# RockChip_RK3588 register map
Vendor: RockChip Electronics Co., Ltd.; Series: RK3588; File version: 0.1
Registers are 32-bit, read-write, no defined reset value unless marked. A register's access mark holds for its fields unless they carry their own. Offsets are from the block's base; [hi:lo] are bit positions; {n}, {i} and the like mark numbered series; 'fields as' and 'values as' point back to an identical list.

## CRU_SECURE
Base 0xFD7D0000
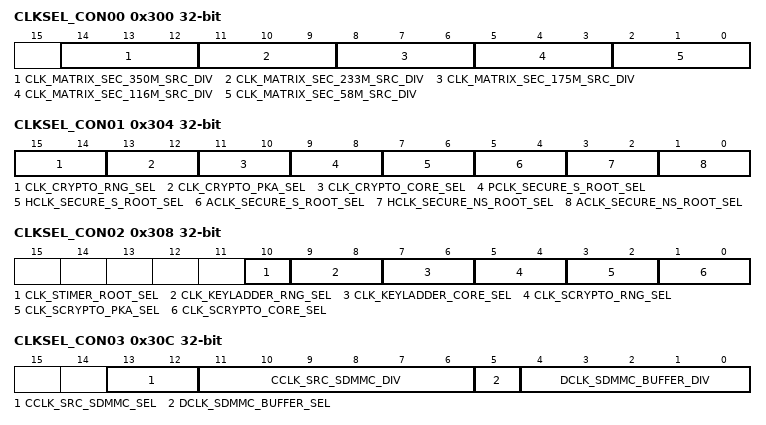
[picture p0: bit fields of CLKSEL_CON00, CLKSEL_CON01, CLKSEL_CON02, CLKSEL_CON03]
0x300 CLKSEL_CON00 — Internal clock select and division register 0
  [14:12] CLK_MATRIX_SEC_350M_SRC_DIV — Divide clk_matrix_sec_350m_src by (div_con + 1).
  [11:9] CLK_MATRIX_SEC_233M_SRC_DIV — Divide clk_matrix_sec_233m_src by (div_con + 1).
  [8:6] CLK_MATRIX_SEC_175M_SRC_DIV — Divide clk_matrix_sec_175m_src by (div_con + 1).
  [5:3] CLK_MATRIX_SEC_116M_SRC_DIV — Divide clk_matrix_sec_116m_src by (div_con + 1).
  [2:0] CLK_MATRIX_SEC_58M_SRC_DIV — Divide clk_matrix_sec_58m_src by (div_con + 1).
0x304 CLKSEL_CON01 — Internal clock select and division register 1
  [15:14] CLK_CRYPTO_RNG_SEL — clk_crypto_rng clock mux.
    0=CLK_MATRIX_SEC_175M_SRC; 1=CLK_MATRIX_SEC_116M_SRC; 2=CLK_MATRIX_SEC_58M_SRC; 3=XIN_OSC0_FUNC
  [13:12] CLK_CRYPTO_PKA_SEL — clk_crypto_pka clock mux.
    0=CLK_MATRIX_SEC_350M_SRC; 1=CLK_MATRIX_SEC_233M_SRC; 2=CLK_MATRIX_SEC_116M_SRC; 3=XIN_OSC0_FUNC
  [11:10] CLK_CRYPTO_CORE_SEL — clk_crypto_core clock mux.
    values as CLK_CRYPTO_PKA_SEL
  [9:8] PCLK_SECURE_S_ROOT_SEL — pclk_secure_s_root clock mux.
    0=CLK_MATRIX_SEC_116M_SRC; 1=CLK_MATRIX_SEC_58M_SRC; 2=XIN_OSC0_FUNC
  [7:6] HCLK_SECURE_S_ROOT_SEL — hclk_secure_s_root clock mux.
    values as CLK_CRYPTO_RNG_SEL
  [5:4] ACLK_SECURE_S_ROOT_SEL — aclk_secure_s_root clock mux.
    values as CLK_CRYPTO_PKA_SEL
  [3:2] HCLK_SECURE_NS_ROOT_SEL — hclk_secure_ns_root clock mux.
    0=CLK_MATRIX_150M_SRC; 1=CLK_MATRIX_100M_SRC; 2=CLK_MATRIX_50M_SRC; 3=XIN_OSC0_FUNC
  [1:0] ACLK_SECURE_NS_ROOT_SEL — aclk_secure_ns_root clock mux.
    0=CLK_MATRIX_350M_SRC; 1=CLK_MATRIX_200M_SRC; 2=CLK_MATRIX_100M_SRC; 3=XIN_OSC0_FUNC
0x308 CLKSEL_CON02 — Internal clock select and division register 2
  [10] CLK_STIMER_ROOT_SEL — clk_stimer_root clock mux.
    0=XIN_OSC0_FUNC; 1=CLK_MATRIX_SEC_116M_SRC
  [9:8] CLK_KEYLADDER_RNG_SEL — clk_keyladder_rng clock mux.
    values as CLKSEL_CON01.CLK_CRYPTO_RNG_SEL
  [7:6] CLK_KEYLADDER_CORE_SEL — clk_keyladder_core clock mux.
    values as CLKSEL_CON01.CLK_CRYPTO_PKA_SEL
  [5:4] CLK_SCRYPTO_RNG_SEL — clk_scrypto_rng clock mux.
    values as CLKSEL_CON01.CLK_CRYPTO_RNG_SEL
  [3:2] CLK_SCRYPTO_PKA_SEL — clk_scrypto_pka clock mux.
    values as CLKSEL_CON01.CLK_CRYPTO_PKA_SEL
  [1:0] CLK_SCRYPTO_CORE_SEL — clk_scrypto_core clock mux.
    values as CLKSEL_CON01.CLK_CRYPTO_PKA_SEL
0x30C CLKSEL_CON03 — Internal clock select and division register 3
  [13:12] CCLK_SRC_SDMMC_SEL — cclk_src_sdmmc clock mux.
    0=CLK_GPLL_MUX; 1=CLK_SPLL_MUX; 2=XIN_OSC0_FUNC
  [11:6] CCLK_SRC_SDMMC_DIV — DT50 division register. Divide cclk_src_sdmmc by (div_con + 1).
  [5] DCLK_SDMMC_BUFFER_SEL — dclk_sdmmc_buffer clock mux.
    0=CLK_GPLL_MUX; 1=CLK_SPLL_MUX
  [4:0] DCLK_SDMMC_BUFFER_DIV — Divide dclk_sdmmc_buffer by (div_con + 1).
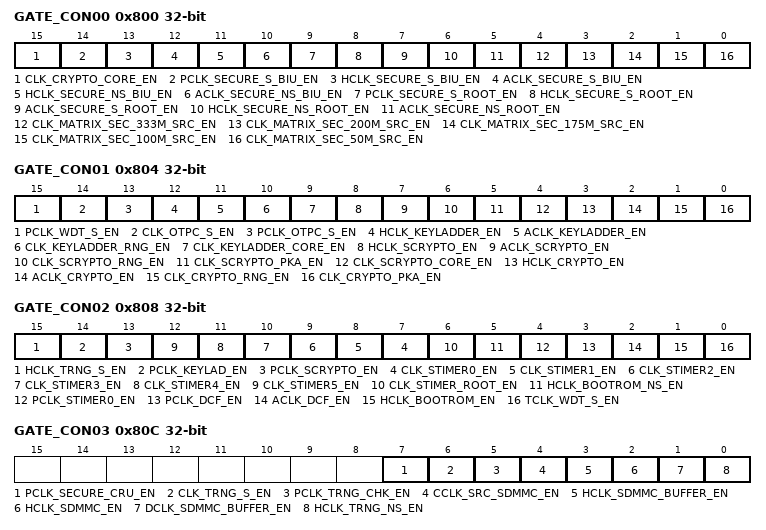
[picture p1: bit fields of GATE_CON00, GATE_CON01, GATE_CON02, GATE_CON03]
0x800 GATE_CON00 — Internal clock gate and division register 0
  [all] fields
    0=ENABLE; 1=DISABLE
  [15] CLK_CRYPTO_CORE_EN — clk_crypto_core clock gating control.
  [14] PCLK_SECURE_S_BIU_EN — pclk_secure_s_biu clock gating control.
  [13] HCLK_SECURE_S_BIU_EN — hclk_secure_s_biu clock gating control.
  [12] ACLK_SECURE_S_BIU_EN — aclk_secure_s_biu clock gating control.
  [11] HCLK_SECURE_NS_BIU_EN — hclk_secure_ns_biu clock gating control.
  [10] ACLK_SECURE_NS_BIU_EN — aclk_secure_ns_biu clock gating control.
  [9] PCLK_SECURE_S_ROOT_EN — pclk_secure_s_root clock gating control.
  [8] HCLK_SECURE_S_ROOT_EN — hclk_secure_s_root clock gating control.
  [7] ACLK_SECURE_S_ROOT_EN — aclk_secure_s_root clock gating control.
  [6] HCLK_SECURE_NS_ROOT_EN — hclk_secure_ns_root clock gating control.
  [5] ACLK_SECURE_NS_ROOT_EN — aclk_secure_ns_root clock gating control.
  [4] CLK_MATRIX_SEC_333M_SRC_EN — clk_matrix_sec_350m_src clock gating control.
  [3] CLK_MATRIX_SEC_200M_SRC_EN — clk_matrix_sec_233m_src clock gating control.
  [2] CLK_MATRIX_SEC_175M_SRC_EN — clk_matrix_sec_175m_src clock gating control.
  [1] CLK_MATRIX_SEC_100M_SRC_EN — clk_matrix_sec_116m_src clock gating control.
  [0] CLK_MATRIX_SEC_50M_SRC_EN — clk_matrix_sec_58m_src clock gating control.
0x804 GATE_CON01 — Internal clock gate and division register 1
  [all] fields
    0=ENABLE; 1=DISABLE
  [15] PCLK_WDT_S_EN — pclk_wdt_s clock gating control.
  [14] CLK_OTPC_S_EN — clk_otpc_s clock gating control.
  [13] PCLK_OTPC_S_EN — pclk_otpc_s clock gating control.
  [12] HCLK_KEYLADDER_EN — hclk_keyladder clock gating control.
  [11] ACLK_KEYLADDER_EN — aclk_keyladder clock gating control.
  [10] CLK_KEYLADDER_RNG_EN — clk_keyladder_rng clock gating control.
  [9] CLK_KEYLADDER_CORE_EN — clk_keyladder_core clock gating control.
  [8] HCLK_SCRYPTO_EN — hclk_scrypto clock gating control.
  [7] ACLK_SCRYPTO_EN — aclk_scrypto clock gating control.
  [6] CLK_SCRYPTO_RNG_EN — clk_scrypto_rng clock gating control.
  [5] CLK_SCRYPTO_PKA_EN — clk_scrypto_pka clock gating control.
  [4] CLK_SCRYPTO_CORE_EN — clk_scrypto_core clock gating control.
  [3] HCLK_CRYPTO_EN — hclk_crypto clock gating control.
  [2] ACLK_CRYPTO_EN — aclk_crypto clock gating control.
  [1] CLK_CRYPTO_RNG_EN — clk_crypto_rng clock gating control.
  [0] CLK_CRYPTO_PKA_EN — clk_crypto_pka clock gating control.
0x808 GATE_CON02 — Internal clock gate and division register 2
  [all] fields
    0=ENABLE; 1=DISABLE
  [15] HCLK_TRNG_S_EN — hclk_trng_s clock gating control.
  [14] PCLK_KEYLAD_EN — pclk_keylad clock gating control.
  [13] PCLK_SCRYPTO_EN — pclk_scrypto clock gating control.
  [n+7] CLK_STIMER{n}_EN (n=0..5) — clk_stimer{n} clock gating control.
  [6] CLK_STIMER_ROOT_EN — clk_stimer_root clock gating control.
  [5] HCLK_BOOTROM_NS_EN — hclk_bootrom_ns clock gating control.
  [4] PCLK_STIMER0_EN — pclk_stimer0 clock gating control.
  [3] PCLK_DCF_EN — pclk_dcf clock gating control.
  [2] ACLK_DCF_EN — aclk_dcf clock gating control.
  [1] HCLK_BOOTROM_EN — hclk_bootrom clock gating control.
  [0] TCLK_WDT_S_EN — tclk_wdt_s clock gating control.
0x80C GATE_CON03 — Internal clock gate and division register 3
  [all] fields
    0=ENABLE; 1=DISABLE
  [7] PCLK_SECURE_CRU_EN — pclk_secure_cru clock gating control.
  [6] CLK_TRNG_S_EN — clk_trng_s clock gating control.
  [5] PCLK_TRNG_CHK_EN — pclk_trng_chk clock gating control.
  [4] CCLK_SRC_SDMMC_EN — cclk_src_sdmmc clock gating control.
  [3] HCLK_SDMMC_BUFFER_EN — hclk_sdmmc_buffer clock gating control.
  [2] HCLK_SDMMC_EN — hclk_sdmmc clock gating control.
  [1] DCLK_SDMMC_BUFFER_EN — dclk_sdmmc_buffer clock gating control.
  [0] HCLK_TRNG_NS_EN — hclk_trng_ns clock gating control.
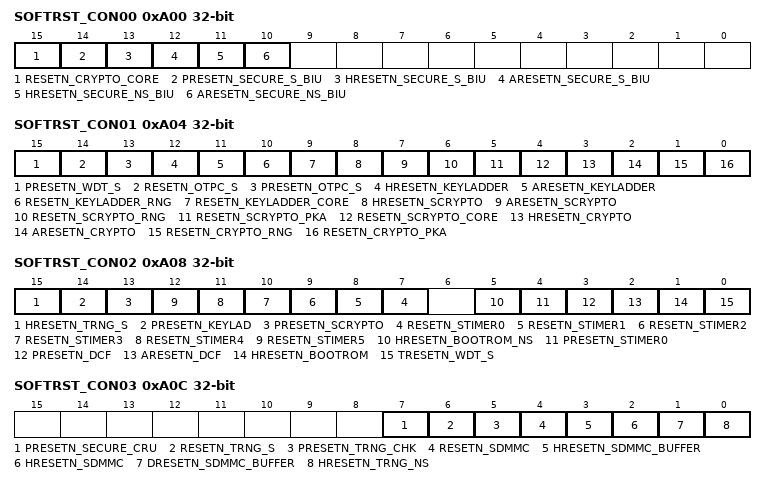
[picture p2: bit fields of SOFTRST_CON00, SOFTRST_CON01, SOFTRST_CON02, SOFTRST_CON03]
0xA00 SOFTRST_CON00 — Internal clock reset register 0
  [15] RESETN_CRYPTO_CORE — When high, reset relative logic
  [14] PRESETN_SECURE_S_BIU — When high, reset relative logic
  [13] HRESETN_SECURE_S_BIU — When high, reset relative logic
  [12] ARESETN_SECURE_S_BIU — When high, reset relative logic
  [11] HRESETN_SECURE_NS_BIU — When high, reset relative logic
  [10] ARESETN_SECURE_NS_BIU — When high, reset relative logic
0xA04 SOFTRST_CON01 — Internal clock reset register 1
  [15] PRESETN_WDT_S — When high, reset relative logic
  [14] RESETN_OTPC_S — When high, reset relative logic
  [13] PRESETN_OTPC_S — When high, reset relative logic
  [12] HRESETN_KEYLADDER — When high, reset relative logic
  [11] ARESETN_KEYLADDER — When high, reset relative logic
  [10] RESETN_KEYLADDER_RNG — When high, reset relative logic
  [9] RESETN_KEYLADDER_CORE — When high, reset relative logic
  [8] HRESETN_SCRYPTO — When high, reset relative logic
  [7] ARESETN_SCRYPTO — When high, reset relative logic
  [6] RESETN_SCRYPTO_RNG — When high, reset relative logic
  [5] RESETN_SCRYPTO_PKA — When high, reset relative logic
  [4] RESETN_SCRYPTO_CORE — When high, reset relative logic
  [3] HRESETN_CRYPTO — When high, reset relative logic
  [2] ARESETN_CRYPTO — When high, reset relative logic
  [1] RESETN_CRYPTO_RNG — When high, reset relative logic
  [0] RESETN_CRYPTO_PKA — When high, reset relative logic
0xA08 SOFTRST_CON02 — Internal clock reset register 2
  [15] HRESETN_TRNG_S — When high, reset relative logic
  [14] PRESETN_KEYLAD — When high, reset relative logic
  [13] PRESETN_SCRYPTO — When high, reset relative logic
  [n+7] RESETN_STIMER{n} (n=0..5) — When high, reset relative logic
  [5] HRESETN_BOOTROM_NS — When high, reset relative logic
  [4] PRESETN_STIMER0 — When high, reset relative logic
  [3] PRESETN_DCF — When high, reset relative logic
  [2] ARESETN_DCF — When high, reset relative logic
  [1] HRESETN_BOOTROM — When high, reset relative logic
  [0] TRESETN_WDT_S — When high, reset relative logic
0xA0C SOFTRST_CON03 — Internal clock reset register 3
  [7] PRESETN_SECURE_CRU — When high, reset relative logic
  [6] RESETN_TRNG_S — When high, reset relative logic
  [5] PRESETN_TRNG_CHK — When high, reset relative logic
  [4] RESETN_SDMMC — When high, reset relative logic
  [3] HRESETN_SDMMC_BUFFER — When high, reset relative logic
  [2] HRESETN_SDMMC — When high, reset relative logic
  [1] DRESETN_SDMMC_BUFFER — When high, reset relative logic
  [0] HRESETN_TRNG_NS — When high, reset relative logic
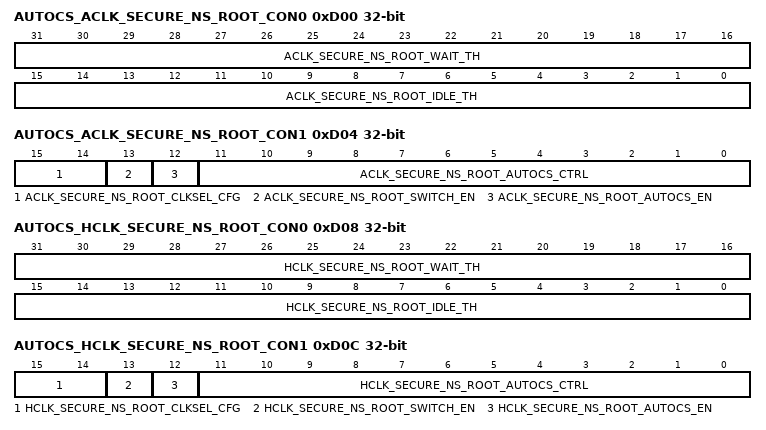
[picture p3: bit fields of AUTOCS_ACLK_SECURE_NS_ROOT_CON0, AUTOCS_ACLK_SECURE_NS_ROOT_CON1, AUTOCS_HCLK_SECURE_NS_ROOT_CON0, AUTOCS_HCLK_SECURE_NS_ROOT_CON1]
0xD00 AUTOCS_ACLK_SECURE_NS_ROOT_CON0 — Auto clock switch control register 0
  [31:16] ACLK_SECURE_NS_ROOT_WAIT_TH — wait_th. Wait time threshold, measured by original clk.
  [15:0] ACLK_SECURE_NS_ROOT_IDLE_TH — idle_th. Idle time threshold, measured by original clk.
0xD04 AUTOCS_ACLK_SECURE_NS_ROOT_CON1 — Auto clock switch control register 1
  [15:14] ACLK_SECURE_NS_ROOT_CLKSEL_CFG — clksel_cfg. Auto switch clock selection.
    0=ORIGINAL_CLK; 1=XIN_OSC0_FUNC_DIV; 2=CLK_RTC_32K
  [13] ACLK_SECURE_NS_ROOT_SWITCH_EN — switch_en.
    1=ENABLE (Enable aclk_secure_ns_root switched to lower frequency when module is inactive.); 0=DISABLE (Disable auto switch function.)
  [12] ACLK_SECURE_NS_ROOT_AUTOCS_EN — autocs_en
    1=ENABLE (Enable aclk_secure_ns_root switch to lower frequency.); 0=DISABLE
  [11:0] ACLK_SECURE_NS_ROOT_AUTOCS_CTRL — autocs_ctrl. Others: Reserved.
    0xFFF=ENABLE (Enable aclk_secure_ns_root switch to lower frequency.); 0=DISABLE
0xD08 AUTOCS_HCLK_SECURE_NS_ROOT_CON0 — Auto clock switch control register 0
  [31:16] HCLK_SECURE_NS_ROOT_WAIT_TH — wait_th. Wait time threshold, measured by original clk.
  [15:0] HCLK_SECURE_NS_ROOT_IDLE_TH — idle_th. Idle time threshold, measured by original clk.
0xD0C AUTOCS_HCLK_SECURE_NS_ROOT_CON1 — Auto clock switch control register 1
  [15:14] HCLK_SECURE_NS_ROOT_CLKSEL_CFG — clksel_cfg. Auto switch clock selection.
    0=ORIGINAL_CLK; 1=XIN_OSC0_FUNC_DIV; 2=CLK_RTC_32K
  [13] HCLK_SECURE_NS_ROOT_SWITCH_EN — switch_en.
    1=ENABLE (Enable hclk_secure_ns_root switched to lower frequency when module is inactive.); 0=DISABLE (Disable auto switch function.)
  [12] HCLK_SECURE_NS_ROOT_AUTOCS_EN — autocs_en
    1=ENABLE (Enable hclk_secure_ns_root switch to lower frequency.); 0=DISABLE
  [11:0] HCLK_SECURE_NS_ROOT_AUTOCS_CTRL — autocs_ctrl. Others: Reserved.
    0xFFF=ENABLE (Enable hclk_secure_ns_root switch to lower frequency.); 0=DISABLE
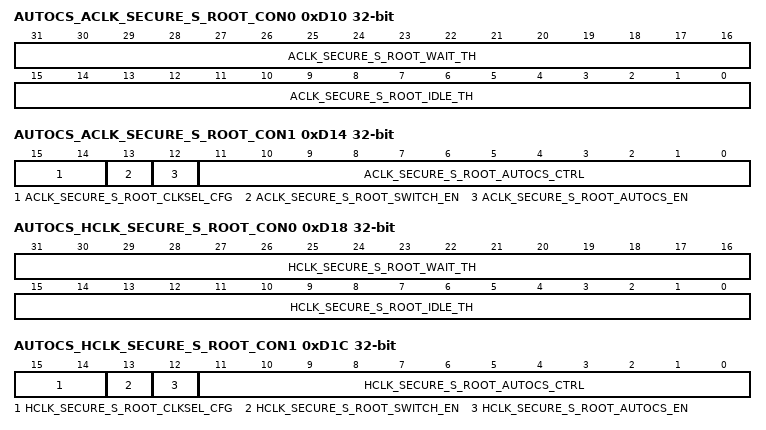
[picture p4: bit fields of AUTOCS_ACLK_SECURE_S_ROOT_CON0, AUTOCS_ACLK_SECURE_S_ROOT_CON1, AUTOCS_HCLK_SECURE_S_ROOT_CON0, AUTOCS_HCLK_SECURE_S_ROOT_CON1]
0xD10 AUTOCS_ACLK_SECURE_S_ROOT_CON0 — Auto clock switch control register 0
  [31:16] ACLK_SECURE_S_ROOT_WAIT_TH — wait_th. Wait time threshold, measured by original clk.
  [15:0] ACLK_SECURE_S_ROOT_IDLE_TH — idle_th. Idle time threshold, measured by original clk.
0xD14 AUTOCS_ACLK_SECURE_S_ROOT_CON1 — Auto clock switch control register 1
  [15:14] ACLK_SECURE_S_ROOT_CLKSEL_CFG — clksel_cfg. Auto switch clock selection.
    0=ORIGINAL_CLK; 1=XIN_OSC0_FUNC_DIV; 2=CLK_RTC_32K
  [13] ACLK_SECURE_S_ROOT_SWITCH_EN — switch_en
    1=ENABLE (Enable aclk_secure_s_root switched to lower frequency when module is inactive.); 0=DISABLE (Disable auto switch function.)
  [12] ACLK_SECURE_S_ROOT_AUTOCS_EN — autocs_en
    1=ENABLE (Enable aclk_secure_s_root switch to lower frequency.); 0=DISABLE
  [11:0] ACLK_SECURE_S_ROOT_AUTOCS_CTRL — autocs_ctrl. Others: Reserved.
    0xFFF=ENABLE (Enable aclk_secure_s_root switch to lower frequency.); 0=DISABLE
0xD18 AUTOCS_HCLK_SECURE_S_ROOT_CON0 — Auto clock switch control register 0
  [31:16] HCLK_SECURE_S_ROOT_WAIT_TH — wait_th. Wait time threshold, measured by original clk.
  [15:0] HCLK_SECURE_S_ROOT_IDLE_TH — idle_th. Idle time threshold, measured by original clk.
0xD1C AUTOCS_HCLK_SECURE_S_ROOT_CON1 — Auto clock switch control register 1
  [15:14] HCLK_SECURE_S_ROOT_CLKSEL_CFG — clksel_cfg. Auto switch clock selection.
    0=ORIGINAL_CLK; 1=XIN_OSC0_FUNC_DIV; 2=CLK_RTC_32K
  [13] HCLK_SECURE_S_ROOT_SWITCH_EN — switch_en
    1=ENABLE (Enable hclk_secure_s_root switched to lower frequency when module is inactive.); 0=DISABLE (Disable auto switch function.)
  [12] HCLK_SECURE_S_ROOT_AUTOCS_EN — autocs_en
    1=ENABLE (Enable hclk_secure_s_root switch to lower frequency.); 0=DISABLE
  [11:0] HCLK_SECURE_S_ROOT_AUTOCS_CTRL — autocs_ctrl. Others: Reserved.
    0xFFF=ENABLE (Enable hclk_secure_s_root switch to lower frequency.); 0=DISABLE
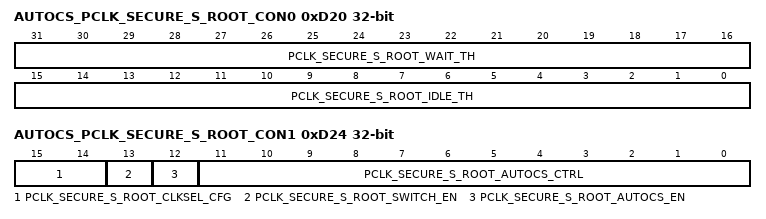
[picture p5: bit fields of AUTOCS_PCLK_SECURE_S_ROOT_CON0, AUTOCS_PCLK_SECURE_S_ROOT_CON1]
0xD20 AUTOCS_PCLK_SECURE_S_ROOT_CON0 — Auto clock switch control register 0
  [31:16] PCLK_SECURE_S_ROOT_WAIT_TH — wait_th. Wait time threshold, measured by original clk.
  [15:0] PCLK_SECURE_S_ROOT_IDLE_TH — idle_th. Idle time threshold, measured by original clk.
0xD24 AUTOCS_PCLK_SECURE_S_ROOT_CON1 — Auto clock switch control register 1
  [15:14] PCLK_SECURE_S_ROOT_CLKSEL_CFG — clksel_cfg. Auto switch clock selection.
    0=ORIGINAL_CLK; 1=XIN_OSC0_FUNC_DIV; 2=CLK_RTC_32K
  [13] PCLK_SECURE_S_ROOT_SWITCH_EN — switch_en
    1=ENABLE (Enable pclk_secure_s_root switched to lower frequency when module is inactive.); 0=DISABLE (Disable auto switch function.)
  [12] PCLK_SECURE_S_ROOT_AUTOCS_EN — autocs_en
    1=ENABLE (Enable pclk_secure_s_root switch to lower frequency.); 0=DISABLE
  [11:0] PCLK_SECURE_S_ROOT_AUTOCS_CTRL — autocs_ctrl. Others: Reserved.
    0xFFF=ENABLE (Enable pclk_secure_s_root switch to lower frequency.); 0=DISABLE
